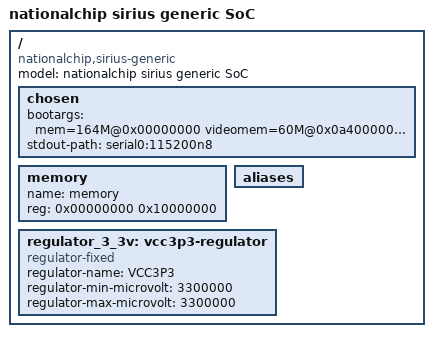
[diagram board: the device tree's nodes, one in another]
/*
 *  Copyright (C) 2013 Steffen Trumtrar <s.trumtrar@pengutronix.de>
 *
 * This program is free software; you can redistribute it and/or modify
 * it under the terms of the GNU General Public License as published by
 * the Free Software Foundation; either version 2 of the License, or
 * (at your option) any later version.
 *
 * This program is distributed in the hope that it will be useful,
 * but WITHOUT ANY WARRANTY; without even the implied warranty of
 * MERCHANTABILITY or FITNESS FOR A PARTICULAR PURPOSE.  See the
 * GNU General Public License for more details.
 *
 * You should have received a copy of the GNU General Public License
 * along with this program.  If not, see <http://www.gnu.org/licenses/>.
 */

/dts-v1/;
/* First 4KB has trampoline code for secondary cores. */
/* /memreserve/ 0x00000000 0x0001000; */

#include "sirius.dtsi"

/ {
	model = "nationalchip sirius generic SoC";
	compatible = "nationalchip,sirius-generic", "nationalchip,sirius";

	chosen {
		bootargs = "mem=164M@0x00000000 videomem=60M@0x0a400000 teemem=32M@0x0e000000 mem_end console=ttyS0,115200 init=/init root=/dev/mtdblock5 rw mtdparts=m25p80:128k@0m(BOOT),64k@128k(TABLE),64k@192k(LOGO),512k@256k(TEE),3392k@768k(KERNEL),12096k@4160k(ROOTFS),64k@16256k(USER),64k@16320k(DATA) mtdparts_end";
		stdout-path = "serial0:115200n8";
	};

	memory {
		name = "memory";
		device_type = "memory";
		reg = <0x00000000 0x10000000>;
	};

	aliases {
		/* this allow the ethaddr uboot environmnet variable contents
		 * to be added to the gmac1 device tree blob.
		 */
	};

	regulator_3_3v: vcc3p3-regulator {
		compatible = "regulator-fixed";
		regulator-name = "VCC3P3";
		regulator-min-microvolt = <3300000>;
		regulator-max-microvolt = <3300000>;
	};
};

